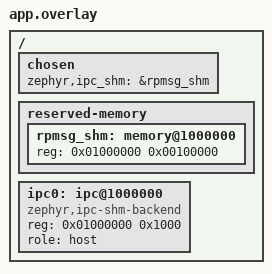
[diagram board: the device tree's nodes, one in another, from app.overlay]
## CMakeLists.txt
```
cmake_minimum_required(VERSION 3.20.0)
find_package(Zephyr REQUIRED HINTS $ENV{ZEPHYR_BASE})
project(Zephyr_qt_bridge)

target_sources(app PRIVATE src/main.c)
zephyr_include_directories(src)
```

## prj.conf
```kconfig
# ----------------RPMsg / OpenAMP----------------

CONFIG_IPM=y 
#Enables the inter processor messaging system to allow data exchange
CONFIG_OPENAMP=y 
#loads the OpenAMP library, which is the standard for communication between different cores
CONFIG_RPMSG_SERVICE=y 
#activates the service layer on top of OpenAMP to make messaging easier 
CONFIG_IPC_SERVICE=y
#enables the intwe peocess communication service
CONFIG_RPMSG_SERVICE_MODE_MASTER=y 
#sets Zephyr as the master in the communication 



#----------------FROM MAIN.C----------------

#Console and data formatting
CONFIG_PRINTK=y 
CONFIG_CBPRINTF_FP_SUPPORT=y  

#Random number generation (sys_rand32_get)
CONFIG_ENTROPY_GENERATOR=y
CONFIG_TEST_RANDOM_GENERATOR=y
CONFIG_TIMER_RANDOM_GENERATOR=y

#Memory management (x86)
CONFIG_X86_COMMON_PAGE_TABLE=n
#disables standard page tables to simplify memory management on x86 platform 
CONFIG_SRAM_REGION_PERMISSIONS=n
#turns off specific RAM permissions to avoid access errors
CONFIG_X86_MMU=n
#disables the MMU (memory management unit) because the memory size doesn't match the standard 4kB blocks
CONFIG_HEAP_MEM_POOL_SIZE=16384 
#allocates dynamic memory RAM for the application use 
CONFIG_MAIN_STACK_SIZE=4096 
#increases the memory space (stack) 
```

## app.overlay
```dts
/ {
	chosen {
		zephyr,ipc_shm = &rpmsg_shm;
	};

	reserved-memory {
		#address-cells = <1>;
		#size-cells = <1>;
		ranges;

		rpmsg_shm: memory@1000000 {
			reg = <0x01000000 0x00100000>;
		};
	};

	ipc0: ipc@1000000 {
		compatible = "zephyr,ipc-shm-backend";
		reg = <0x01000000 0x1000>; 
		role = "host";
		status = "okay";
	};
};
```

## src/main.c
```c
/* Necessary libraries for kernel functions and IPC*/
#include <zephyr/kernel.h>
#include <zephyr/device.h>
#include <zephyr/random/random.h>
#include <stdio.h>
#include <zephyr/ipc/rpmsg_service.h>

/*define a name for the communication channel*/
#define ENDPOINT_NAME "rpmsg-client"
static int endpoint_id;

/* From dashboard to sensor (currently unused but required) */
int rpmsg_recv_callback(struct rpmsg_endpoint *myEndpoint, void *data, size_t len, uint32_t src, void *priv)
{
    return RPMSG_SUCCESS;
}

int main(void)
{
    char message_buffer[128];
    int check_value;

    printk("Zephyr Dashboard Bridge Start\n");

    /* register the endpoint to start the communication service*/
    endpoint_id = rpmsg_service_register_endpoint(ENDPOINT_NAME, rpmsg_recv_callback);
    
    /*Check if the initialization was successful*/
    if (endpoint_id < 0) {
        printk("Error: %d\n", endpoint_id);
    }

    /* infinite loop to simulate real-time sensor monitoring*/
    while (1) {
        /* generate random values */
        float temperature = (float)(sys_rand32_get() % 701) / 10.0f - 20.0f;
        float humidity    = (float)(sys_rand32_get() % 701) / 10.0f + 30.0f;
        float pressure    = (float)(sys_rand32_get() % 3501) / 10.0f + 900.0f;
        float airQuality  = (float)(sys_rand32_get() % 7001) / 10.0f;
        float light       = (float)(sys_rand32_get() % 70001) / 10.0f;

        /* format the data into a string*/
        int len = snprintf(message_buffer, sizeof(message_buffer), "DATA|%.1f|%.1f|%.1f|%.1f|%.1f\n", 
                          (double)temperature, (double)humidity, (double)pressure, 
                          (double)airQuality, (double)light);

        /*print the string to the serial console for python bridge*/
        printk("%s", message_buffer);

        if (endpoint_id >= 0) {
            /* forward the message through the RPMsg channel*/
            check_value = rpmsg_service_send(endpoint_id, message_buffer, len);
            if (check_value < 0) {
            }
        }

        k_sleep(K_SECONDS(2));
    }

    return 0;
}
```
